# STM32N657 register map
File version: 1.0
CPU: CM55 r0p1, little endian, no MPU, FPU, vendor SysTick, 8 interrupt priority bits
Registers are 32-bit, read-write, reset 0x0 unless marked. A register's access mark holds for its fields unless they carry their own. Offsets are from the block's base; [hi:lo] are bit positions; 'fields as' and 'values as' point back to an identical list.

## SAI1 — Serial audio interface
Base 0x42005800
Same registers: SAI2 0x42005C00, SAI1_S 0x52005800, SAI2_S 0x52005C00
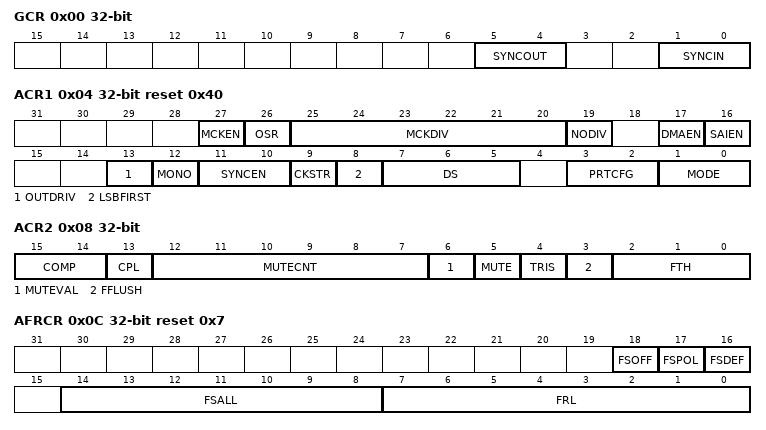
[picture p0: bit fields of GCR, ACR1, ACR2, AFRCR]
0x00 GCR — SAI global configuration register
  [5:4] SYNCOUT — Synchronization outputs
  [1:0] SYNCIN — Synchronization outputs
0x04 ACR1 reset 0x40 — SAI configuration register 1
  [27] MCKEN — Master clock generation enable
  [26] OSR — Oversampling ratio for master clock
  [25:20] MCKDIV — Master clock divider
  [19] NODIV — No divider
  [17] DMAEN — DMA enable
  [16] SAIEN — Audio block enable
  [13] OUTDRIV — Output drive
  [12] MONO — Mono mode
  [11:10] SYNCEN — Synchronization enable
  [9] CKSTR — Clock strobing edge
  [8] LSBFIRST — Least significant bit first
  [7:5] DS — Data size
  [3:2] PRTCFG — Protocol configuration
  [1:0] MODE — SAIx audio block mode
0x08 ACR2 access per field — SAI configuration register 2
  [15:14] COMP rw — Companding mode.
  [13] CPL rw — Complement bit.
  [12:7] MUTECNT rw — Mute counter.
  [6] MUTEVAL rw — Mute value.
  [5] MUTE rw
  [4] TRIS rw — Tristate management on data line.
  [3] FFLUSH wo — FIFO flush.
  [2:0] FTH rw — FIFO threshold.
0x0C AFRCR reset 0x7 — SAI frame configuration register
  [18] FSOFF — Frame synchronization offset.
  [17] FSPOL — Frame synchronization polarity.
  [16] FSDEF — Frame synchronization definition.
  [14:8] FSALL — Frame synchronization active level length.
  [7:0] FRL — Frame length.
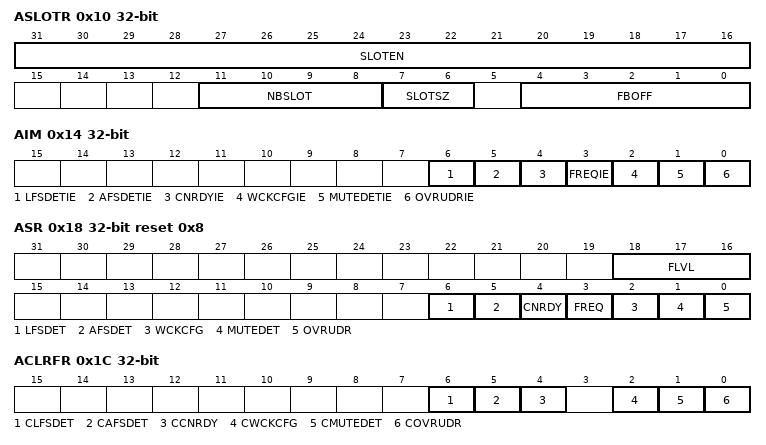
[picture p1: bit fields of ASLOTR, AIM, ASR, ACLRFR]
0x10 ASLOTR — SAI slot register
  [31:16] SLOTEN — Slot enable.
  [11:8] NBSLOT — Number of slots in an audio frame.
  [7:6] SLOTSZ — Slot size
  [4:0] FBOFF — First bit offset
0x14 AIM — SAI interrupt mask register
  [6] LFSDETIE — Late frame synchronization detection interrupt enable.
  [5] AFSDETIE — Anticipated frame synchronization detection interrupt enable.
  [4] CNRDYIE — Codec not ready interrupt enable (AC'97).
  [3] FREQIE — FIFO request interrupt enable.
  [2] WCKCFGIE — Wrong clock configuration interrupt enable.
  [1] MUTEDETIE — Mute detection interrupt enable.
  [0] OVRUDRIE — Overrun/underrun interrupt enable.
0x18 ASR ro reset 0x8 — SAI status register
  [18:16] FLVL — FIFO level threshold.
  [6] LFSDET — Late frame synchronization detection.
  [5] AFSDET — Anticipated frame synchronization detection.
  [4] CNRDY — Codec not ready.
  [3] FREQ — FIFO request.
  [2] WCKCFG — Wrong clock configuration flag.
  [1] MUTEDET — Mute detection.
  [0] OVRUDR — Overrun / underrun.
0x1C ACLRFR wo — SAI clear flag register
  [6] CLFSDET — Clear late frame synchronization detection flag.
  [5] CAFSDET — Clear anticipated frame synchronization detection flag.
  [4] CCNRDY — Clear Codec not ready flag.
  [2] CWCKCFG — Clear wrong clock configuration flag.
  [1] CMUTEDET — Mute detection flag.
  [0] COVRUDR — Clear overrun / underrun.
0x20 ADR — SAI data register
  [31:0] DATA
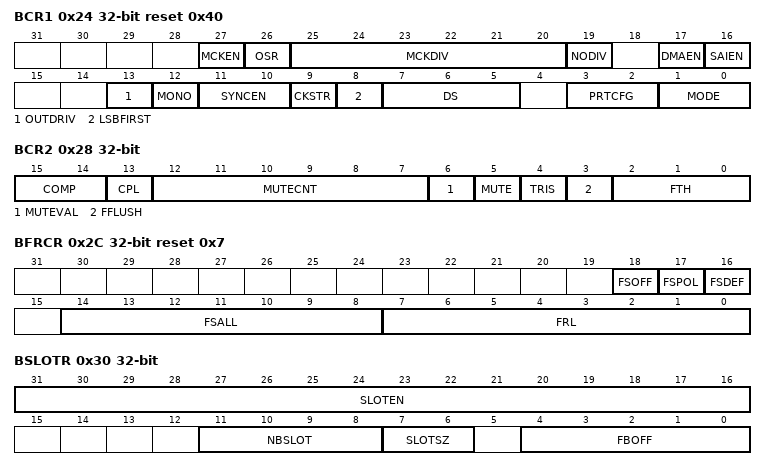
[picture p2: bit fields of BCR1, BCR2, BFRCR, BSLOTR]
0x24 BCR1 reset 0x40 — SAI configuration register 1
  fields as ACR1
0x28 BCR2 access per field — SAI configuration register 2
  fields as ACR2
0x2C BFRCR reset 0x7 — SAI frame configuration register
  fields as AFRCR
0x30 BSLOTR — SAI slot register
  fields as ASLOTR
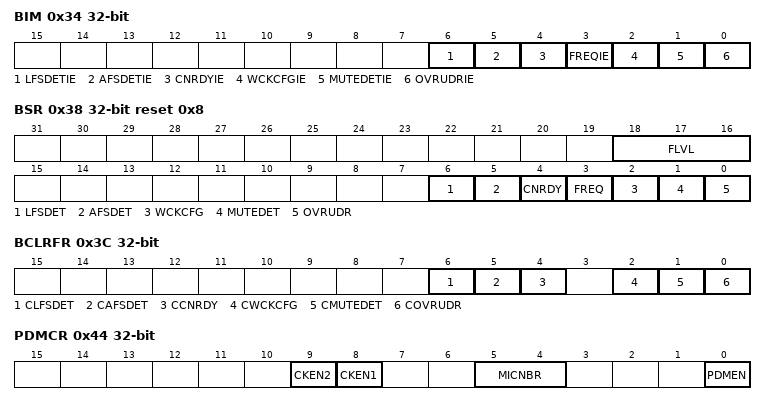
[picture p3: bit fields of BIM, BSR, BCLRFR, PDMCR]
0x34 BIM — SAI interrupt mask register
  fields as AIM
0x38 BSR ro reset 0x8 — SAI status register
  fields as ASR
0x3C BCLRFR wo — SAI clear flag register
  fields as ACLRFR
0x40 BDR — SAI data register
  [31:0] DATA
0x44 PDMCR — SAI PDM control register
  [9] CKEN2 — Clock enable of bitstream clock number 2
  [8] CKEN1 — Clock enable of bitstream clock number 1
  [5:4] MICNBR — Number of microphones
  [0] PDMEN — PDM enable
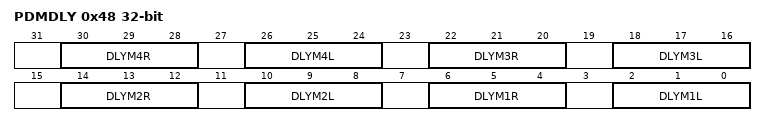
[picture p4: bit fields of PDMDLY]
0x48 PDMDLY — SAI PDM delay register
  [30:28] DLYM4R — Delay line for second microphone of pair 4
  [26:24] DLYM4L — Delay line for first microphone of pair 4
  [22:20] DLYM3R — Delay line for second microphone of pair 3
  [18:16] DLYM3L — Delay line for first microphone of pair 3
  [14:12] DLYM2R — Delay line for second microphone of pair 2
  [10:8] DLYM2L — Delay line for first microphone of pair 2
  [6:4] DLYM1R — Delay line adjust for second microphone of pair 1
  [2:0] DLYM1L — Delay line adjust for first microphone of pair 1
